# PIC18F45Q43 register map
Vendor: Microchip
Registers are 8-bit, read-write, reset 0x0 unless marked. A register's access mark holds for its fields unless they carry their own. Addresses are absolute, and some are shared; only a register's first bit layout is shown; [hi:lo] are bit positions.

## DOS_xxxx_Interrupts
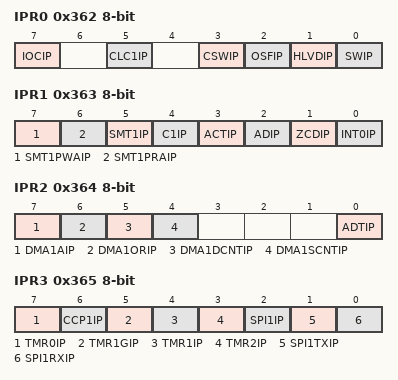
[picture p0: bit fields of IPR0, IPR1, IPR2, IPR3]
0x362 IPR0
  [7] IOCIP, [5] CLC1IP, [3] CSWIP, [2] OSFIP, [1] HLVDIP, [0] SWIP
0x363 IPR1
  [7] SMT1PWAIP, [6] SMT1PRAIP, [5] SMT1IP, [4] C1IP, [3] ACTIP, [2] ADIP, [1] ZCDIP, [0] INT0IP
0x364 IPR2
  [7] DMA1AIP, [6] DMA1ORIP, [5] DMA1DCNTIP, [4] DMA1SCNTIP, [0] ADTIP
0x365 IPR3
  [7] TMR0IP, [6] CCP1IP, [5] TMR1GIP, [4] TMR1IP, [3] TMR2IP, [2] SPI1IP, [1] SPI1TXIP, [0] SPI1RXIP
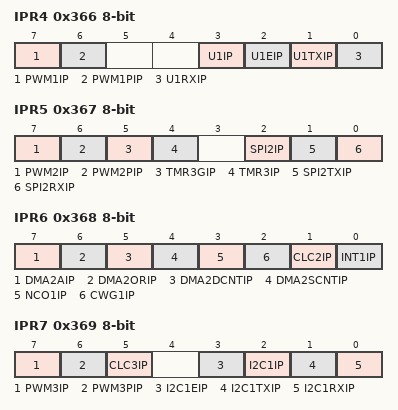
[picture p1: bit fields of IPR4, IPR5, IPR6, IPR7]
0x366 IPR4
  [7] PWM1IP, [6] PWM1PIP, [3] U1IP, [2] U1EIP, [1] U1TXIP, [0] U1RXIP
0x367 IPR5
  [7] PWM2IP, [6] PWM2PIP, [5] TMR3GIP, [4] TMR3IP, [2] SPI2IP, [1] SPI2TXIP, [0] SPI2RXIP
0x368 IPR6
  [7] DMA2AIP, [6] DMA2ORIP, [5] DMA2DCNTIP, [4] DMA2SCNTIP, [3] NCO1IP, [2] CWG1IP, [1] CLC2IP, [0] INT1IP
0x369 IPR7
  [7] PWM3IP, [6] PWM3PIP, [5] CLC3IP, [3] I2C1EIP, [2] I2C1IP, [1] I2C1TXIP, [0] I2C1RXIP
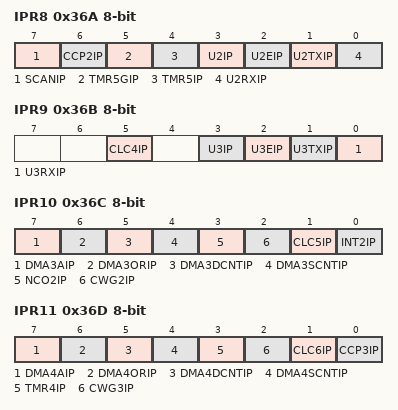
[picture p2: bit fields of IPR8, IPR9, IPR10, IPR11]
0x36A IPR8 reset not defined — (power-on value xxxxx000)
  [7] SCANIP, [6] CCP2IP, [5] TMR5GIP, [4] TMR5IP, [3] U2IP, [2] U2EIP, [1] U2TXIP, [0] U2RXIP
0x36B IPR9 reset not defined — (power-on value --x-xxxx)
  [5] CLC4IP, [3] U3IP, [2] U3EIP, [1] U3TXIP, [0] U3RXIP
0x36C IPR10 reset not defined — (power-on value xxxxxxxx)
  [7] DMA3AIP, [6] DMA3ORIP, [5] DMA3DCNTIP, [4] DMA3SCNTIP, [3] NCO2IP, [2] CWG2IP, [1] CLC5IP, [0] INT2IP
0x36D IPR11 reset not defined — (power-on value xxxxxxxx)
  [7] DMA4AIP, [6] DMA4ORIP, [5] DMA4DCNTIP, [4] DMA4SCNTIP, [3] TMR4IP, [2] CWG3IP, [1] CLC6IP, [0] CCP3IP
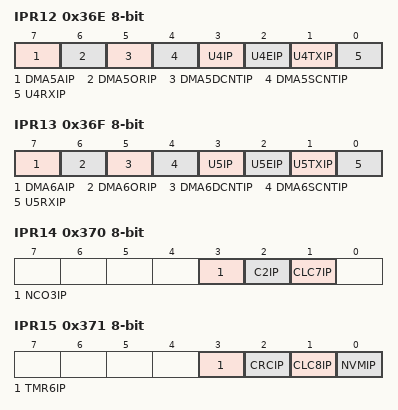
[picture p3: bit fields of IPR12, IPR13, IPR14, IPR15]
0x36E IPR12 reset not defined — (power-on value xxxxxxxx)
  [7] DMA5AIP, [6] DMA5ORIP, [5] DMA5DCNTIP, [4] DMA5SCNTIP, [3] U4IP, [2] U4EIP, [1] U4TXIP, [0] U4RXIP
0x36F IPR13 reset not defined — (power-on value xxxxxxxx)
  [7] DMA6AIP, [6] DMA6ORIP, [5] DMA6DCNTIP, [4] DMA6SCNTIP, [3] U5IP, [2] U5EIP, [1] U5TXIP, [0] U5RXIP
0x370 IPR14 reset not defined — (power-on value ----xxx-)
  [3] NCO3IP, [2] C2IP, [1] CLC7IP
0x371 IPR15 reset not defined — (power-on value ----xxxx)
  [3] TMR6IP, [2] CRCIP, [1] CLC8IP, [0] NVMIP
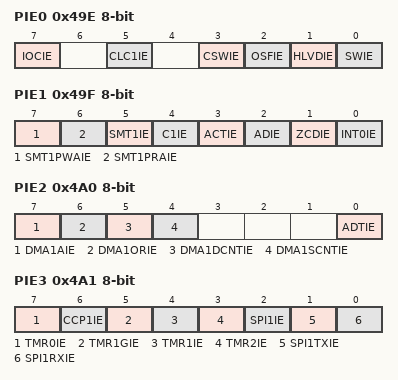
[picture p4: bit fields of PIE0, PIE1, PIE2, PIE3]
0x49E PIE0
  [7] IOCIE, [5] CLC1IE, [3] CSWIE, [2] OSFIE, [1] HLVDIE, [0] SWIE
0x49F PIE1
  [7] SMT1PWAIE, [6] SMT1PRAIE, [5] SMT1IE, [4] C1IE, [3] ACTIE, [2] ADIE, [1] ZCDIE, [0] INT0IE
0x4A0 PIE2
  [7] DMA1AIE, [6] DMA1ORIE, [5] DMA1DCNTIE, [4] DMA1SCNTIE, [0] ADTIE
0x4A1 PIE3
  [7] TMR0IE, [6] CCP1IE, [5] TMR1GIE, [4] TMR1IE, [3] TMR2IE, [2] SPI1IE, [1] SPI1TXIE, [0] SPI1RXIE
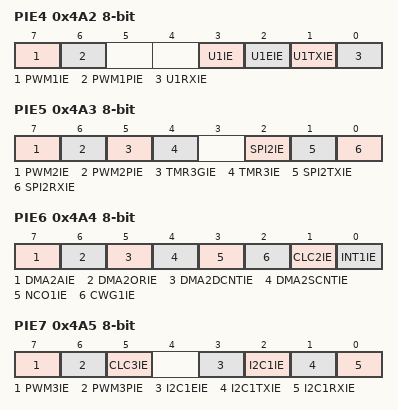
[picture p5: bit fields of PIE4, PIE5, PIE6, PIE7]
0x4A2 PIE4
  [7] PWM1IE, [6] PWM1PIE, [3] U1IE, [2] U1EIE, [1] U1TXIE, [0] U1RXIE
0x4A3 PIE5
  [7] PWM2IE, [6] PWM2PIE, [5] TMR3GIE, [4] TMR3IE, [2] SPI2IE, [1] SPI2TXIE, [0] SPI2RXIE
0x4A4 PIE6
  [7] DMA2AIE, [6] DMA2ORIE, [5] DMA2DCNTIE, [4] DMA2SCNTIE, [3] NCO1IE, [2] CWG1IE, [1] CLC2IE, [0] INT1IE
0x4A5 PIE7
  [7] PWM3IE, [6] PWM3PIE, [5] CLC3IE, [3] I2C1EIE, [2] I2C1IE, [1] I2C1TXIE, [0] I2C1RXIE
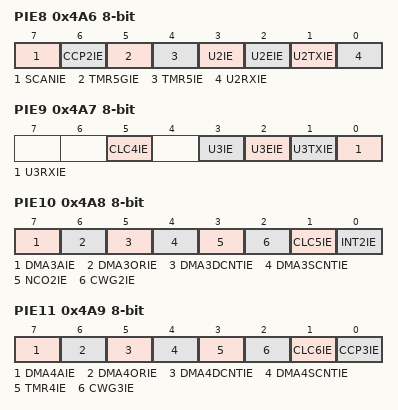
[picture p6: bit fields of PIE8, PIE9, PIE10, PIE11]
0x4A6 PIE8 reset not defined — (power-on value xxxxx000)
  [7] SCANIE, [6] CCP2IE, [5] TMR5GIE, [4] TMR5IE, [3] U2IE, [2] U2EIE, [1] U2TXIE, [0] U2RXIE
0x4A7 PIE9 reset not defined — (power-on value --x-xxxx)
  [5] CLC4IE, [3] U3IE, [2] U3EIE, [1] U3TXIE, [0] U3RXIE
0x4A8 PIE10 reset not defined — (power-on value xxxxxxxx)
  [7] DMA3AIE, [6] DMA3ORIE, [5] DMA3DCNTIE, [4] DMA3SCNTIE, [3] NCO2IE, [2] CWG2IE, [1] CLC5IE, [0] INT2IE
0x4A9 PIE11 reset not defined — (power-on value xxxxxxxx)
  [7] DMA4AIE, [6] DMA4ORIE, [5] DMA4DCNTIE, [4] DMA4SCNTIE, [3] TMR4IE, [2] CWG3IE, [1] CLC6IE, [0] CCP3IE
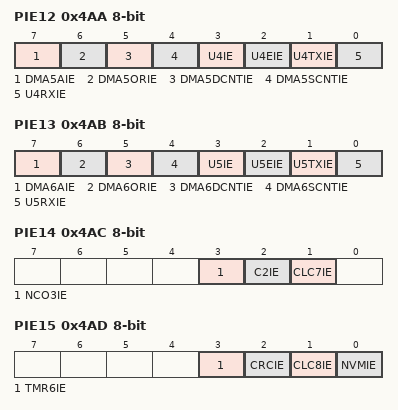
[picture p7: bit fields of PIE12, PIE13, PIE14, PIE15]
0x4AA PIE12 reset not defined — (power-on value xxxxxxxx)
  [7] DMA5AIE, [6] DMA5ORIE, [5] DMA5DCNTIE, [4] DMA5SCNTIE, [3] U4IE, [2] U4EIE, [1] U4TXIE, [0] U4RXIE
0x4AB PIE13 reset not defined — (power-on value xxxxxxxx)
  [7] DMA6AIE, [6] DMA6ORIE, [5] DMA6DCNTIE, [4] DMA6SCNTIE, [3] U5IE, [2] U5EIE, [1] U5TXIE, [0] U5RXIE
0x4AC PIE14 reset not defined — (power-on value ----xxx-)
  [3] NCO3IE, [2] C2IE, [1] CLC7IE
0x4AD PIE15 reset not defined — (power-on value ----xxxx)
  [3] TMR6IE, [2] CRCIE, [1] CLC8IE, [0] NVMIE
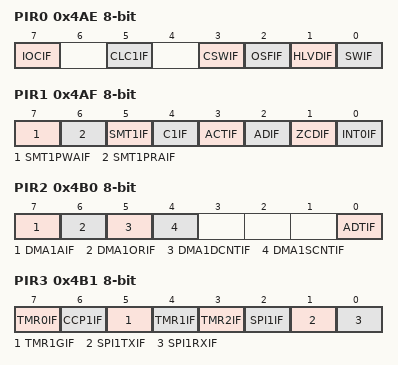
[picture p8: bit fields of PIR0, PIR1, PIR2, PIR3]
0x4AE PIR0
  [7] IOCIF ro, [5] CLC1IF, [3] CSWIF, [2] OSFIF ro, [1] HLVDIF, [0] SWIF
0x4AF PIR1
  [7] SMT1PWAIF, [6] SMT1PRAIF, [5] SMT1IF, [4] C1IF, [3] ACTIF, [2] ADIF, [1] ZCDIF, [0] INT0IF
0x4B0 PIR2
  [7] DMA1AIF, [6] DMA1ORIF, [5] DMA1DCNTIF, [4] DMA1SCNTIF, [0] ADTIF
0x4B1 PIR3
  [7] TMR0IF, [6] CCP1IF, [5] TMR1GIF, [4] TMR1IF, [3] TMR2IF, [2] SPI1IF ro, [1] SPI1TXIF ro, [0] SPI1RXIF ro
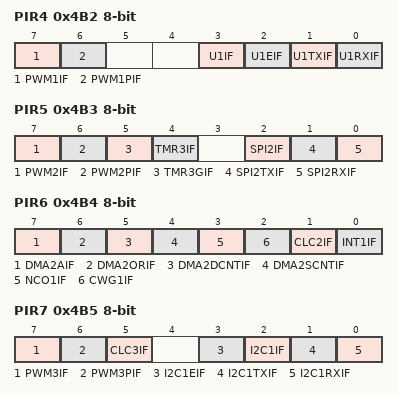
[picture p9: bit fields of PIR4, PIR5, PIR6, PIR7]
0x4B2 PIR4
  [7] PWM1IF ro, [6] PWM1PIF, [3] U1IF ro, [2] U1EIF ro, [1] U1TXIF ro, [0] U1RXIF ro
0x4B3 PIR5
  [7] PWM2IF ro, [6] PWM2PIF, [5] TMR3GIF, [4] TMR3IF, [2] SPI2IF ro, [1] SPI2TXIF ro, [0] SPI2RXIF ro
0x4B4 PIR6
  [7] DMA2AIF, [6] DMA2ORIF, [5] DMA2DCNTIF, [4] DMA2SCNTIF, [3] NCO1IF, [2] CWG1IF, [1] CLC2IF, [0] INT1IF
0x4B5 PIR7
  [7] PWM3IF ro, [6] PWM3PIF, [5] CLC3IF, [3] I2C1EIF ro, [2] I2C1IF ro, [1] I2C1TXIF ro, [0] I2C1RXIF ro
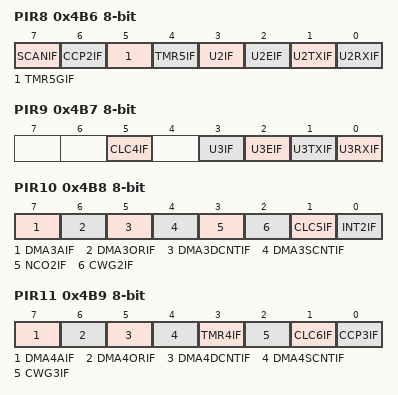
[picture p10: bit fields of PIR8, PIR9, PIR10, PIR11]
0x4B6 PIR8 reset not defined — (power-on value xxxxx000)
  [7] SCANIF, [6] CCP2IF, [5] TMR5GIF, [4] TMR5IF, [3] U2IF, [2] U2EIF, [1] U2TXIF, [0] U2RXIF
0x4B7 PIR9 reset not defined — (power-on value --x-xxxx)
  [5] CLC4IF, [3] U3IF, [2] U3EIF, [1] U3TXIF, [0] U3RXIF
0x4B8 PIR10 reset not defined — (power-on value xxxxxxxx)
  [7] DMA3AIF, [6] DMA3ORIF, [5] DMA3DCNTIF, [4] DMA3SCNTIF, [3] NCO2IF, [2] CWG2IF, [1] CLC5IF, [0] INT2IF
0x4B9 PIR11 reset not defined — (power-on value xxxxxxxx)
  [7] DMA4AIF, [6] DMA4ORIF, [5] DMA4DCNTIF, [4] DMA4SCNTIF, [3] TMR4IF, [2] CWG3IF, [1] CLC6IF, [0] CCP3IF
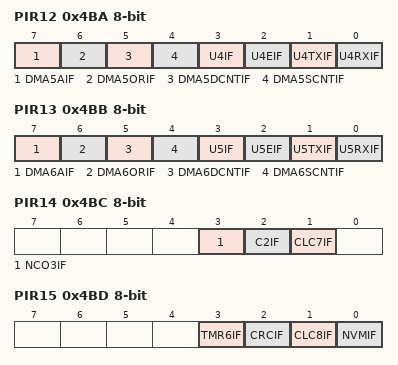
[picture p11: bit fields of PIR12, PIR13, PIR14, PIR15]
0x4BA PIR12 reset not defined — (power-on value xxxxxxxx)
  [7] DMA5AIF, [6] DMA5ORIF, [5] DMA5DCNTIF, [4] DMA5SCNTIF, [3] U4IF, [2] U4EIF, [1] U4TXIF, [0] U4RXIF
0x4BB PIR13 reset not defined — (power-on value xxxxxxxx)
  [7] DMA6AIF, [6] DMA6ORIF, [5] DMA6DCNTIF, [4] DMA6SCNTIF, [3] U5IF, [2] U5EIF, [1] U5TXIF, [0] U5RXIF
0x4BC PIR14 reset not defined — (power-on value ----xxx-)
  [3] NCO3IF, [2] C2IF, [1] CLC7IF
0x4BD PIR15 reset not defined — (power-on value ----xxxx)
  [3] TMR6IF, [2] CRCIF, [1] CLC8IF, [0] NVMIF
